# PRU-ICSS_0_ECC_CFG_local register map
Vendor: Texas Instruments
Peripheral module from a debugger description file (folder 66AK2G0x_66AK2G1x).
Registers are 32-bit, access not given, reset 0x0 unless marked. A register's access mark holds for its fields unless they carry their own. Offsets are as the file gives them; lines under a group give offsets from that group; [hi:lo] are bit positions; {n}, {i} and the like mark numbered series; 'fields as' and 'values as' point back to an identical list; <NAME> marks a mode.

## PRU-ICSS_0_ECC_CFG
0x00 ECC_REVISION ro reset not defined
  [31:0] REV — TI internal data. Identifies revision of peripheral.
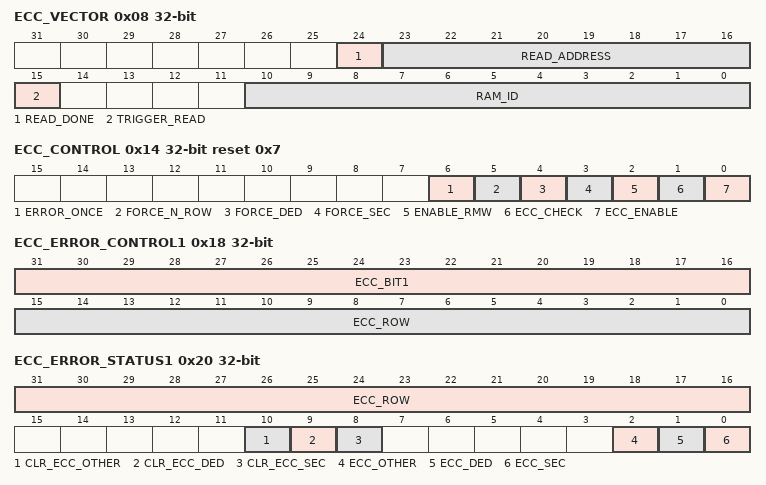
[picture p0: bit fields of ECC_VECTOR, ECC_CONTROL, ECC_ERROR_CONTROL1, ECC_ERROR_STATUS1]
0x08 ECC_VECTOR access per field
  [24] READ_DONE ro — Status to indicate if read on the serial VBUS is complete.
  [23:16] READ_ADDRESS rw — Read address. Can be any of the registers (10h – 24h).
  [15] TRIGGER_READ rw — Write 1 to trigger a read on the serial VBUS.
  [10:0] RAM_ID rw — Value written to select the corresponding ECC RAM for control or status.
0x0C ECC_MISC_STATUS ro reset 0x5
  [10:0] NUM_RAMS — Indicates the number of RAMs serviced by the ECC aggregator.
0x10 ECC_WRAPPER_REVISION ro reset not defined
  [31:0] REV — TI internal data. Identifies revision of peripheral.
0x14 ECC_CONTROL access per field reset 0x7
  [6] ERROR_ONCE rw — If this bit is set, the FORCE_SEC/ FORCE_DED will inject an error to the specified row only once. The FORCE_SEC bit will be cleared once a writeback happens. If writeback is not enabled, this error will be cleared the cycle following the read when the data is corrected. For double-bit errors, the FORCE_DED bit will be cleared the cycle following the double-bit error. Any subsequent reads will not force an error.
  [5] FORCE_N_ROW rw — Force single/double-bit error on the next RAM read.
  [4] FORCE_DED rw — Force double-bit error. Cleared the cycle following the error if ERROR_ONCE is asserted.
  [3] FORCE_SEC rw — Force single-bit error. Cleared on a writeback or the cycle following the error if ERROR_ONCE is asserted.
  [2] ENABLE_RMW rw — Enable read-modify-write on partial word writes.
  [1] ECC_CHECK rw — Enable ECC check. ECC is completely bypassed if both ECC_ENABLE and ECC_CHECK are 0.
  [0] ECC_ENABLE rw — Enable ECC generation.
0x18 ECC_ERROR_CONTROL1 rw
  [31:16] ECC_BIT1 — Column/ Data bit that needs to be flipped when FORCE_SEC or FORCE_DED is set.
  [15:0] ECC_ROW — Row address where FORCE_SEC or FORCE_DED needs to be applied. This is ignored if FORCE_N_ROW is set.
0x1C ECC_ERROR_CONTROL2 access per field
  [15:0] ECC_BIT2 rw — Data bit that needs to be flipped when FORCE_DED is set
0x20 ECC_ERROR_STATUS1
  [31:16] ECC_ROW ro — Indicates the row/address where the single or double-bit error occurred.
  [10] CLR_ECC_OTHER — 1 indicates a successive single-bit error. Writing a 1 clears the status bit. (access RW1C)
  [9] CLR_ECC_DED — 1 indicates a pending double-bit error. Writing a 1 clears the status bit. (access RW1C)
  [8] CLR_ECC_SEC — 1 indicates a pending single-bit error. Writing a 1 clears the status bit. (access RW1C)
  [2] ECC_OTHER — 1 indicates that successive single-bit errors have occurred while a writeback is still pending. Software can also write a 1 to set the pending status and write a ‘1’ to the corresponding clear bit to clear the status. (access RW1S)
  [1] ECC_DED — 1 indicates pending double-bit error. Since the double-bit error from the ECC logic is a pulsed interrupt, this is also a status set register. The software can also write a ‘1’ to set the pending status and write a ‘1’ to the corresponding clear bit to clear the status. (access RW1S)
  [0] ECC_SEC — 1 indicates pending single-bit error status. Since the single-bit error from the ECC logic is a pulsed interrupt, this is also a status set register. The software can also write a ‘1’ to set the pending status and write a ‘1’ to the corresponding clear bit to clear the status. (access RW1S)
0x24 ECC_ERROR_STATUS2 ro
  [15:0] ECC_BIT1 — Indicates the bit position in the RAM data that is in error. For eg: a value of 1 indicates that bit 1 in the data is in error. This is valid only for single bit errors (sec).
0x3C ECC_EOI
  [0] EOI_WR — Write to this register indicates that software has acknowledged the pending interrupt and the next interrupt can be sent to the host. (access RW1S)
{0x40+4i} ECC_INT_STATUS_{i} ro (i=0..14)
  [4:0] SRC_INTR — Level interrupt status from each ECC RAM.
{0x80+4i} ECC_INT_ENABLE_{i} (i=0..14)
  [4:0] ENABLE — Write 1 to enable interrupt from the associated ECC RAM. (access RW1S)
{0xC0+4i} ECC_INT_CLEAR_{i} (i=0..14)
  [4:0] ENABLE_CLEAR — Write 1 to disable interrupt from the associated ECC RAM. (access RW1C)
